VERSION ""

NS_ :

BS_:

BU_: VCU EAO
VAL_TABLE_ VT_Button_Stuck 3 "Not available" 2 "Stuck Error" 1 "Reserved" 0 "Not Stuck" ;
VAL_TABLE_ VT_Button_State 3 "Not available" 2 "Error" 1 "Button Pressed" 0 "Button Released" ;

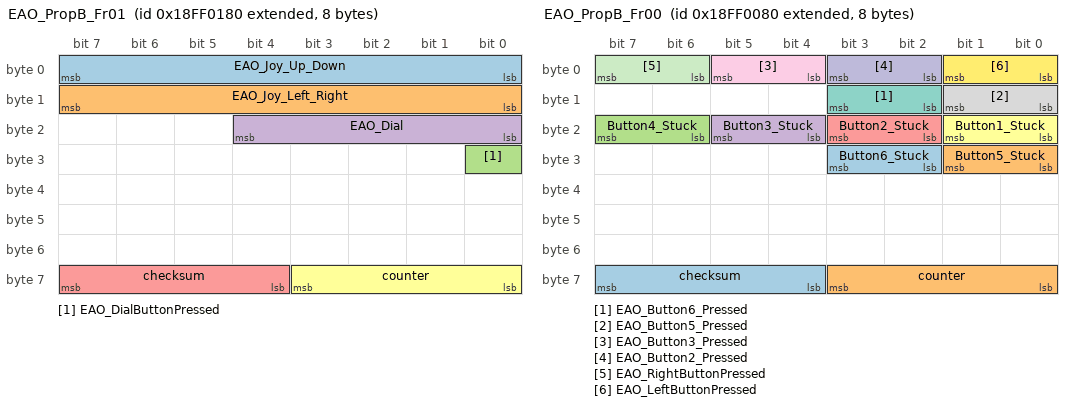
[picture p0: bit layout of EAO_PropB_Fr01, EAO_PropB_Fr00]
BO_ 2566848896 EAO_PropB_Fr01: 8 EAO
 SG_ EAO_Joy_Up_Down : 0|8@1+ (1,-125) [-127|128] "" Vector__XXX
 SG_ EAO_Joy_Left_Right : 8|8@1+ (1,-125) [-125|130] "" Vector__XXX
 SG_ EAO_DialButtonPressed : 24|1@1+ (1,0) [0|1] "" Vector__XXX
 SG_ EAO_Dial : 16|5@1+ (1,0) [0|31] "" Vector__XXX
 SG_ checksum : 60|4@1+ (1,0) [0|15] "" Vector__XXX
 SG_ counter : 56|4@1+ (1,0) [0|15] "" Vector__XXX

BO_ 2566848640 EAO_PropB_Fr00: 8 EAO
 SG_ Button6_Stuck : 26|2@1+ (1,0) [0|3] "" Vector__XXX
 SG_ Button5_Stuck : 24|2@1+ (1,0) [0|3] "" Vector__XXX
 SG_ Button4_Stuck : 22|2@1+ (1,0) [0|3] "" Vector__XXX
 SG_ Button3_Stuck : 20|2@1+ (1,0) [0|3] "" Vector__XXX
 SG_ Button2_Stuck : 18|2@1+ (1,0) [0|3] "" Vector__XXX
 SG_ Button1_Stuck : 16|2@1+ (1,0) [0|3] "" Vector__XXX
 SG_ EAO_Button6_Pressed : 10|2@1+ (1,0) [0|3] "" Vector__XXX
 SG_ EAO_Button5_Pressed : 8|2@1+ (1,0) [0|3] "" Vector__XXX
 SG_ EAO_Button3_Pressed : 4|2@1+ (1,0) [0|3] "" Vector__XXX
 SG_ EAO_Button2_Pressed : 2|2@1+ (1,0) [0|3] "" Vector__XXX
 SG_ EAO_RightButtonPressed : 6|2@1+ (1,0) [0|3] "" Vector__XXX
 SG_ EAO_LeftButtonPressed : 0|2@1+ (1,0) [0|3] "" Vector__XXX
 SG_ checksum : 60|4@1+ (1,0) [0|15] "" Vector__XXX
 SG_ counter : 56|4@1+ (1,0) [0|15] "" Vector__XXX

BO_ 2565799808 EAO_ACL: 8 EAO

BA_DEF_ BU_  "NmStationAddress" HEX 0 0;
BA_DEF_ BO_  "GenMsgCycleTime" INT 0 0;
BA_DEF_ BO_  "GenMsgSendType" ENUM  "Cyclic","not_used","not_used","not_used","not_used","Cyclic","not_used","IfActive";
BA_DEF_DEF_  "NmStationAddress" 0;
BA_DEF_DEF_  "GenMsgCycleTime" 0;
BA_DEF_DEF_  "GenMsgSendType" "not_used";
BA_ "NmStationAddress" BU_ VCU 97;
BA_ "NmStationAddress" BU_ EAO 128;
BA_ "GenMsgSendType" BO_ 2566848896 0;
BA_ "GenMsgCycleTime" BO_ 2566848896 100;
BA_ "GenMsgSendType" BO_ 2566848640 0;
BA_ "GenMsgCycleTime" BO_ 2566848640 100;
BA_ "GenMsgSendType" BO_ 2565799808 7;
VAL_ 2566848640 Button6_Stuck 3 "Not available" 2 "Stuck Error" 1 "Reserved" 0 "Not Stuck" ;
VAL_ 2566848640 Button5_Stuck 3 "Not available" 2 "Stuck Error" 1 "Reserved" 0 "Not Stuck" ;
VAL_ 2566848640 Button4_Stuck 3 "Not available" 2 "Stuck Error" 1 "Reserved" 0 "Not Stuck" ;
VAL_ 2566848640 Button3_Stuck 3 "Not available" 2 "Stuck Error" 1 "Reserved" 0 "Not Stuck" ;
VAL_ 2566848640 Button2_Stuck 3 "Not available" 2 "Stuck Error" 1 "Reserved" 0 "Not Stuck" ;
VAL_ 2566848640 Button1_Stuck 3 "Not available" 2 "Stuck Error" 1 "Reserved" 0 "Not Stuck" ;
VAL_ 2566848640 EAO_Button6_Pressed 3 "Not available" 2 "Error" 1 "Button Pressed" 0 "Button Released" ;
VAL_ 2566848640 EAO_Button5_Pressed 3 "Not available" 2 "Error" 1 "Button Pressed" 0 "Button Released" ;
VAL_ 2566848640 EAO_Button3_Pressed 3 "Not available" 2 "Error" 1 "Button Pressed" 0 "Button Released" ;
VAL_ 2566848640 EAO_Button2_Pressed 3 "Not available" 2 "Error" 1 "Button Pressed" 0 "Button Released" ;
VAL_ 2566848640 EAO_RightButtonPressed 3 "Not available" 2 "Error" 1 "Button Pressed" 0 "Button Released" ;
VAL_ 2566848640 EAO_LeftButtonPressed 3 "Not available" 2 "Error" 1 "Button Pressed" 0 "Button Released" ;
